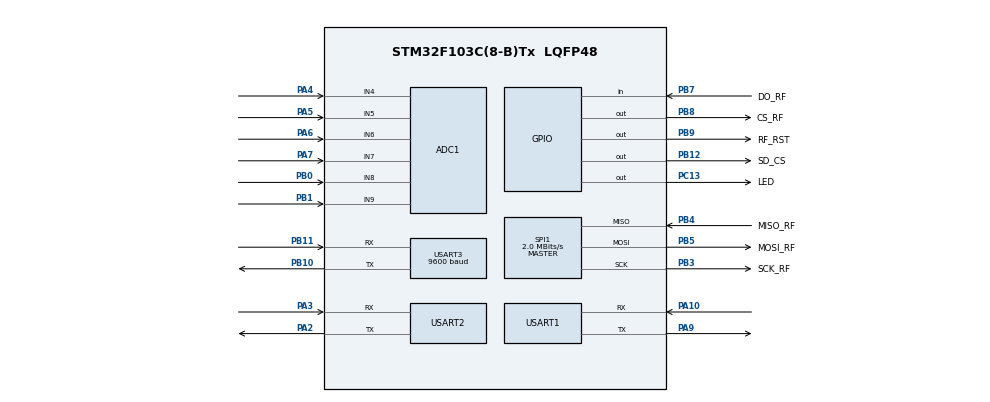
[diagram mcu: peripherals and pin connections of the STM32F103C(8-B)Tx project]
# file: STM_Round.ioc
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Mcu.Family=STM32F1
NVIC.USART3_IRQn=true\:1\:0\:true\:true\:true\:5\:true\:true
NVIC.DMA1_Channel5_IRQn=true\:1\:0\:true\:true\:true\:1\:false\:true
SPI1.VirtualType=VM_MASTER
PB10.Mode=Asynchronous
ADC1.ContinuousConvMode=ENABLE
PB11.Signal=USART3_RX
Dma.USART2_RX.1.MemDataAlignment=DMA_MDATAALIGN_BYTE
ProjectManager.StackSize=0x400
PD1-OSC_OUT.Signal=RCC_OSC_OUT
USART3.BaudRate=9600
ADC1.Channel-5\#ChannelRegularConversion=ADC_CHANNEL_9
ADC1.Channel-3\#ChannelRegularConversion=ADC_CHANNEL_7
SPI1.Direction=SPI_DIRECTION_2LINES
ADC1.Channel-2\#ChannelRegularConversion=ADC_CHANNEL_6
Dma.USART2_RX.1.PeriphInc=DMA_PINC_DISABLE
SPI1.CalculateBaudRate=2.0 MBits/s
Dma.USART2_RX.1.MemInc=DMA_MINC_ENABLE
Dma.USART1_RX.0.Priority=DMA_PRIORITY_LOW
ADC1.Channel-0\#ChannelRegularConversion=ADC_CHANNEL_4
PB3.Mode=Full_Duplex_Master
PB12.GPIO_Label=SD_CS
ADC1.SamplingTime-4\#ChannelRegularConversion=ADC_SAMPLETIME_239CYCLES_5
ADC1.Rank-2\#ChannelRegularConversion=3
PB4.Mode=Full_Duplex_Master
Dma.ADC1.2.MemDataAlignment=DMA_MDATAALIGN_HALFWORD
PA14.Mode=Serial_Wire
PB5.Mode=Full_Duplex_Master
SH.ADCx_IN8.0=ADC1_IN8,IN8
PB8.PinState=GPIO_PIN_SET
Dma.ADC1.2.Direction=DMA_PERIPH_TO_MEMORY
PB7.Signal=GPIO_Input
Dma.USART1_RX.0.MemInc=DMA_MINC_ENABLE
ADC1.SamplingTime-0\#ChannelRegularConversion=ADC_SAMPLETIME_239CYCLES_5
PB7.GPIO_Label=DO_RF
Mcu.Package=LQFP48
PB9.Signal=GPIO_Output
PB1.Signal=ADCx_IN9
PA6.Signal=ADCx_IN6
USART2.VirtualMode=VM_ASYNC
PA10.Signal=USART1_RX
SH.ADCx_IN9.0=ADC1_IN9,IN9
PB5.GPIO_Label=MOSI_RF
Dma.Request2=ADC1
Dma.Request1=USART2_RX
Dma.USART1_RX.0.Mode=DMA_NORMAL
NVIC.USART1_IRQn=true\:1\:0\:true\:true\:true\:3\:true\:true
Dma.USART2_RX.1.Mode=DMA_NORMAL
Dma.Request0=USART1_RX
SPI1.BaudRatePrescaler=SPI_BAUDRATEPRESCALER_4
Dma.USART1_RX.0.Instance=DMA1_Channel5
ADC1.Rank-4\#ChannelRegularConversion=5
PB4.Signal=SPI1_MISO
Dma.ADC1.2.Mode=DMA_CIRCULAR
PA3.Signal=USART2_RX
PB3.GPIO_Label=SCK_RF
NVIC.DMA1_Channel6_IRQn=true\:1\:0\:true\:true\:true\:2\:false\:true
Dma.USART2_RX.1.Priority=DMA_PRIORITY_LOW
ADC1.Rank-0\#ChannelRegularConversion=1
PD1-OSC_OUT.Mode=HSE-External-Oscillator
Dma.USART1_RX.0.PeriphDataAlignment=DMA_PDATAALIGN_BYTE
PB9.GPIO_Label=RF_RST
ADC1.Channel-4\#ChannelRegularConversion=ADC_CHANNEL_8
PA10.Mode=Asynchronous
SH.ADCx_IN6.0=ADC1_IN6,IN6
Dma.ADC1.2.PeriphDataAlignment=DMA_PDATAALIGN_HALFWORD
PC13-TAMPER-RTC.Signal=GPIO_Output
PD0-OSC_IN.Signal=RCC_OSC_IN
NVIC.USART2_IRQn=true\:1\:0\:true\:true\:true\:4\:true\:true
ADC1.SamplingTime-2\#ChannelRegularConversion=ADC_SAMPLETIME_239CYCLES_5
RCC.ADCPresc=RCC_ADCPCLK2_DIV8
PA3.Mode=Asynchronous
PA13.Signal=SYS_JTMS-SWDIO
PB8.GPIO_Label=CS_RF
PA9.Mode=Asynchronous
Dma.ADC1.2.MemInc=DMA_MINC_ENABLE
PB11.Mode=Asynchronous
ProjectManager.TargetToolchain=STM32CubeIDE
SH.ADCx_IN7.0=ADC1_IN7,IN7
Dma.USART1_RX.0.Direction=DMA_PERIPH_TO_MEMORY
PA9.Signal=USART1_TX
ADC1.Channel-1\#ChannelRegularConversion=ADC_CHANNEL_5
Dma.USART1_RX.0.PeriphInc=DMA_PINC_DISABLE
PB12.GPIO_Speed=GPIO_SPEED_FREQ_MEDIUM
Dma.USART2_RX.1.Instance=DMA1_Channel6
PD0-OSC_IN.Mode=HSE-External-Oscillator
PB10.Signal=USART3_TX
Dma.USART2_RX.1.Direction=DMA_PERIPH_TO_MEMORY
PA5.Signal=ADCx_IN5
Dma.USART2_RX.1.PeriphDataAlignment=DMA_PDATAALIGN_BYTE
board=custom
PC13-TAMPER-RTC.GPIO_Label=LED
RCC.APB2Freq_Value=8000000
PB4.GPIO_Label=MISO_RF
SPI1.Mode=SPI_MODE_MASTER
Dma.USART1_RX.0.MemDataAlignment=DMA_MDATAALIGN_BYTE
SH.ADCx_IN4.0=ADC1_IN4,IN4
ADC1.NbrOfConversion=6
PA13.Mode=Serial_Wire
Mcu.Name=STM32F103C(8-B)Tx
PA2.Signal=USART2_TX
Dma.ADC1.2.Instance=DMA1_Channel1
PB3.Signal=SPI1_SCK
PA4.Signal=ADCx_IN4
ADC1.SamplingTime-1\#ChannelRegularConversion=ADC_SAMPLETIME_239CYCLES_5
Dma.ADC1.2.Priority=DMA_PRIORITY_LOW
PB5.Signal=SPI1_MOSI
ADC1.master=1
ADC1.Rank-3\#ChannelRegularConversion=4
ADC1.SamplingTime-3\#ChannelRegularConversion=ADC_SAMPLETIME_239CYCLES_5
Dma.ADC1.2.PeriphInc=DMA_PINC_DISABLE
USART3.VirtualMode=VM_ASYNC
USART1.VirtualMode=VM_ASYNC
PB9.PinState=GPIO_PIN_SET
ADC1.Rank-1\#ChannelRegularConversion=2
PA14.Signal=SYS_JTCK-SWCLK
ProjectManager.HeapSize=0x200
ADC1.SamplingTime-5\#ChannelRegularConversion=ADC_SAMPLETIME_239CYCLES_5
SH.ADCx_IN5.0=ADC1_IN5,IN5
NVIC.PriorityGroup=NVIC_PRIORITYGROUP_4
ADC1.NbrOfConversionFlag=1
PA2.Mode=Asynchronous
PB8.Signal=GPIO_Output
NVIC.DMA1_Channel1_IRQn=true\:0\:0\:false\:false\:true\:false\:true
RCC.APB1Freq_Value=8000000
PB8.GPIO_Speed=GPIO_SPEED_FREQ_MEDIUM
PB0.Signal=ADCx_IN8
ADC1.Rank-5\#ChannelRegularConversion=6
PB12.Signal=GPIO_Output
PA7.Signal=ADCx_IN7

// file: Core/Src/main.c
/* USER CODE BEGIN Header */
/**
 ******************************************************************************
 * @file           : main.c
 * @brief          : Main program body
 ******************************************************************************
 * @attention
 *
 * <h2><center>&copy; Copyright (c) 2021 STMicroelectronics.
 * All rights reserved.</center></h2>
 *
 * This software component is licensed by ST under BSD 3-Clause license,
 * the "License"; You may not use this file except in compliance with the
 * License. You may obtain a copy of the License at:
 *                        opensource.org/licenses/BSD-3-Clause
 *
 ******************************************************************************
 */
/* USER CODE END Header */
#include "main.h"
#include "adc.h"
#include "dma.h"
#include "spi.h"
#include "usart.h"
#include "gpio.h"

/* USER CODE BEGIN Includes */

#include "Funkcje.h"
#include <stdio.h>

/* USER CODE END Includes */

/* USER CODE BEGIN PV */

char odp[100] = "TNWN;DSTA";

/* USER CODE END PV */

void SystemClock_Config(void);
static void MX_NVIC_Init(void);

int main(void)
{

  /* MCU Configuration--------------------------------------------------------*/

  /* Reset of all peripherals, Initializes the Flash interface and the Systick. */
  HAL_Init();

  /* Configure the system clock */
  SystemClock_Config();

  /* Initialize all configured peripherals */
  MX_GPIO_Init();
  MX_DMA_Init();
  MX_SPI1_Init();
  MX_USART1_UART_Init();
  MX_USART2_UART_Init();
  MX_USART3_UART_Init();
  MX_ADC1_Init();

  /* Initialize interrupts */
  MX_NVIC_Init();
  /* USER CODE BEGIN 2 */

	HAL_Delay(1000);
	initAll();

  /* USER CODE END 2 */

  /* Infinite loop */
  /* USER CODE BEGIN WHILE */
	while (1) {

		if (uwTick - tfsStruct.gpsFrameTimer > gpsPeriod) {
			tfsStruct.gpsFrameTimer = uwTick;

			sendData(); //!
		}

    /* USER CODE END WHILE */

	}
}

void SystemClock_Config(void)
{
  RCC_OscInitTypeDef RCC_OscInitStruct = {0};
  RCC_ClkInitTypeDef RCC_ClkInitStruct = {0};
  RCC_PeriphCLKInitTypeDef PeriphClkInit = {0};

  /** Initializes the RCC Oscillators according to the specified parameters
  * in the RCC_OscInitTypeDef structure.
  */
  RCC_OscInitStruct.OscillatorType = RCC_OSCILLATORTYPE_HSI;
  RCC_OscInitStruct.HSIState = RCC_HSI_ON;
  RCC_OscInitStruct.HSICalibrationValue = RCC_HSICALIBRATION_DEFAULT;
  RCC_OscInitStruct.PLL.PLLState = RCC_PLL_NONE;
  if (HAL_RCC_OscConfig(&RCC_OscInitStruct) != HAL_OK)
  {
    Error_Handler();
  }
  /** Initializes the CPU, AHB and APB buses clocks
  */
  RCC_ClkInitStruct.ClockType = RCC_CLOCKTYPE_HCLK|RCC_CLOCKTYPE_SYSCLK
                              |RCC_CLOCKTYPE_PCLK1|RCC_CLOCKTYPE_PCLK2;
  RCC_ClkInitStruct.SYSCLKSource = RCC_SYSCLKSOURCE_HSI;
  RCC_ClkInitStruct.AHBCLKDivider = RCC_SYSCLK_DIV1;
  RCC_ClkInitStruct.APB1CLKDivider = RCC_HCLK_DIV1;
  RCC_ClkInitStruct.APB2CLKDivider = RCC_HCLK_DIV1;

  if (HAL_RCC_ClockConfig(&RCC_ClkInitStruct, FLASH_LATENCY_0) != HAL_OK)
  {
    Error_Handler();
  }
  PeriphClkInit.PeriphClockSelection = RCC_PERIPHCLK_ADC;
  PeriphClkInit.AdcClockSelection = RCC_ADCPCLK2_DIV8;
  if (HAL_RCCEx_PeriphCLKConfig(&PeriphClkInit) != HAL_OK)
  {
    Error_Handler();
  }
}

/**
  * @brief NVIC Configuration.
  * @retval None
  */
static void MX_NVIC_Init(void)
{
  /* DMA1_Channel5_IRQn interrupt configuration */
  HAL_NVIC_SetPriority(DMA1_Channel5_IRQn, 1, 0);
  HAL_NVIC_EnableIRQ(DMA1_Channel5_IRQn);
  /* DMA1_Channel6_IRQn interrupt configuration */
  HAL_NVIC_SetPriority(DMA1_Channel6_IRQn, 1, 0);
  HAL_NVIC_EnableIRQ(DMA1_Channel6_IRQn);
  /* USART1_IRQn interrupt configuration */
  HAL_NVIC_SetPriority(USART1_IRQn, 1, 0);
  HAL_NVIC_EnableIRQ(USART1_IRQn);
  /* USART2_IRQn interrupt configuration */
  HAL_NVIC_SetPriority(USART2_IRQn, 1, 0);
  HAL_NVIC_EnableIRQ(USART2_IRQn);
  /* USART3_IRQn interrupt configuration */
  HAL_NVIC_SetPriority(USART3_IRQn, 1, 0);
  HAL_NVIC_EnableIRQ(USART3_IRQn);
}

void Error_Handler(void)
{
	__disable_irq();
	while (1) {
	}
}

/************************ (C) COPYRIGHT STMicroelectronics *****END OF FILE****/
